# LOOPMUX register map
Vendor: Texas Instruments
Peripheral module from a debugger description file (folder UCD3138R032RSM).
Registers are 32-bit, read-write, no defined reset value unless marked. A register's access mark holds for its fields unless they carry their own. Offsets are as the file gives them; lines under a group give offsets from that group; [hi:lo] are bit positions; {n}, {i} and the like mark numbered series; 'fields as' and 'values as' point back to an identical list; <NAME> marks a mode.

## LOOPMUX — Top Module UCDLOOPMUX
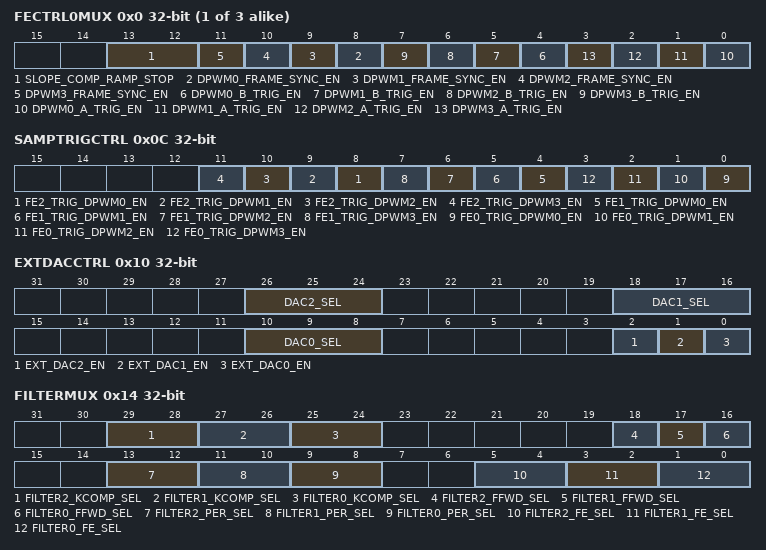
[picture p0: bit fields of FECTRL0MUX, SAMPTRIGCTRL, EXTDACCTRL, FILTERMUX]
{0x0+4i} FECTRL{i}MUX (i=0..2) — Front End Control {i} Mux Register
  [13:12] SLOPE_COMP_RAMP_STOP — Selects the PCMC module source for stop ramp signal in the event of peak current detection
  [n+8] DPWM{n}_FRAME_SYNC_EN (n=0..3) — Enables DPWM Trigger from DPWM {n} Frame Sync to Front End Control
    1=routed (DPWM {n} Frame Sync routed to Front End Control); 0=not_routed (DPWM {n} Frame Sync not routed to Front End Control (Default))
  [n+4] DPWM{n}_B_TRIG_EN (n=0..3) — Enables DPWM Trigger from DPWM {n} PWM-B to Front End Contro
    1=routed (DPWM {n} PWM-B trigger routed to Front End Control); 0=not_routed (DPWM {n} PWM-B trigger not routed to Front End Control (Default))
  [n] DPWM{n}_A_TRIG_EN (n=0..3) — Enables DPWM Trigger from DPWM {n} PWM-A to Front End Contro
    1=routed (DPWM {n} PWM-A trigger routed to Front End Control); 0=not_routed (DPWM {n} PWM-A trigger not routed to Front End Control (Default))
0x0C SAMPTRIGCTRL — Sample Trigger Control Register
  [n+8] FE2_TRIG_DPWM{n}_EN (n=0..3) — Enables Sample Trigger from DPWM {n} to Front End Control 2
    1=routed (DPWM {n} Sample Trigger routed to Front End Control 2); 0=not_routed (DPWM {n} Sample Trigger not routed to Front End Control 2 (Default))
  [n+4] FE1_TRIG_DPWM{n}_EN (n=0..3) — Enables Sample Trigger from DPWM {n} to Front End Control 1
    1=routed (DPWM {n} Sample Trigger routed to Front End Control 1); 0=not_routed (DPWM {n} Sample Trigger not routed to Front End Control 1 (Default))
  [n] FE0_TRIG_DPWM{n}_EN (n=0..3) — Enables Sample Trigger from DPWM {n} to Front End Control 0
    1=routed (DPWM {n} Sample Trigger routed to Front End Control 0); 0=not_routed (DPWM {n} Sample Trigger not routed to Front End Control 0 (Default))
0x10 EXTDACCTRL access per field — External DAC Control Register
  [26:24] DAC2_SEL rw — Configures DAC 2 setpoint in External DAC Mode
    6=FILTER_2 (Filter 2 Output Selected); 5=FILTER_1 (Filter 1 Output Selected); 4=FILTER_0 (Filter 0 Output Selected); 3=CP (Output of Constant Power Module Selected); 1=DAC_1 (DAC 1 Setpoint Selected); 0=DAC_0 (DAC 0 Setpoint Selected (Default))
  [18:16] DAC1_SEL rw — Configures DAC 1 setpoint in External DAC Mode
    6=FILTER_2 (Filter 2 Output Selected); 5=FILTER_1 (Filter 1 Output Selected); 4=FILTER_0 (Filter 0 Output Selected); 3=CP (Output of Constant Power Module Selected); 2=DAC_2 (DAC 2 Setpoint Selected); 0=DAC_0 (DAC 0 Setpoint Selected (Default))
  [10:8] DAC0_SEL rw — Configures DAC 0 setpoint in External DAC Mode
    6=FILTER_2 (Filter 2 Output Selected); 5=FILTER_1 (Filter 1 Output Selected); 4=FILTER_0 (Filter 0 Output Selected); 3=CP (Output of Constant Power Module Selected); 2=DAC_2 (DAC 2 Setpoint Selected); 1=DAC_1 (DAC 1 Setpoint Selected (Default))
  [2] EXT_DAC2_EN rw — External DAC 1 Mode Enable
    1=enable (External DAC Mode enabled, DAC 2 setpoint driven by DAC1_SEL configuration); 0=disabled (External DAC Mode disabled. DAC 2 setpoint driven from Front End Control Module (Default))
  [1] EXT_DAC1_EN rw — External DAC 1 Mode Enable
    1=enable (External DAC Mode enabled, DAC 1 setpoint driven by DAC1_SEL configuration); 0=disabled (External DAC Mode disabled. DAC 1 setpoint driven from Front End Control Module (Default))
  [0] EXT_DAC0_EN rw — External DAC 1 Mode Enable
    1=enable (External DAC Mode enabled, DAC 0 setpoint driven by DAC1_SEL configuration); 0=disabled (External DAC Mode disabled. DAC 0 setpoint driven from Front End Control Module (Default))
0x14 FILTERMUX access per field
  [29:28] FILTER2_KCOMP_SEL rw — Selects KComp value routed to Filter 2 Module
    2=KCOMP_2 (KComp 2 Value Selected); 1=KCOMP_1 (KComp 1 Value Selected); 0=KCOMP_0 (KComp 0 Value Selected (Default))
  [27:26] FILTER1_KCOMP_SEL rw — Selects KComp value routed to Filter 1 Module
    values as FILTER2_KCOMP_SEL
  [25:24] FILTER0_KCOMP_SEL rw — Selects KComp value routed to Filter 0 Module
    values as FILTER2_KCOMP_SEL
  [18] FILTER2_FFWD_SEL rw — Configures Feedforward value routed to Filter 2 Module
    1=FILTER_1 (Filter 1 Value Selected); 0=FILTER_0 (Filter0 Value Selected (Default))
  [17] FILTER1_FFWD_SEL rw — Configures Feedforward value routed to Filter 1 Module
    1=FILTER_2 (Filter 2 Value Selected); 0=FILTER_0 (Filter0 Value Selected (Default))
  [16] FILTER0_FFWD_SEL rw — Configures Feedforward value routed to Filter 0 Module
    1=FILTER_2 (Filter 2 Value Selected); 0=FILTER_1 (Filter 1 Value Selected (Default))
  [13:12] FILTER2_PER_SEL rw — Selects source of switching cycle period for Filter 2 Module
    3=DPWM_3 (DPWM 3 Switching Period); 2=DPWM_2 (DPWM 2 Switching Period); 1=DPWM_1 (DPWM 1 Switching Period); 0=DPWM_0 (DPWM 0 Switching Period (Default))
  [11:10] FILTER1_PER_SEL rw — Selects source of switching cycle period for Filter 1 Module
    values as FILTER2_PER_SEL
  [9:8] FILTER0_PER_SEL rw — Selects source of switching cycle period for Filter 0 Module
    values as FILTER2_PER_SEL
  [5:4] FILTER2_FE_SEL rw — Selects which Front End Module provides data for Filter 2 Module
    2=FE_2 (Front End Module 2 provides data to Filter(Default)); 1=FE_1 (Front End Module 1 provides data to Filter); 0=FE_0 (Front End Module 0 provides data to Filter)
  [3:2] FILTER1_FE_SEL rw — Selects which Front End Module provides data for Filter 1 Module
    2=FE_2 (Front End Module 2 provides data to Filter); 1=FE_1 (Front End Module 1 provides data to Filter(Default)); 0=FE_0 (Front End Module 0 provides data to Filter)
  [1:0] FILTER0_FE_SEL rw — Selects which Front End Module provides data for Filter 0 Module
    2=FE_2 (Front End Module 2 provides data to Filter); 1=FE_1 (Front End Module 1 provides data to Filter); 0=FE_0 (Front End Module 0 provides data to Filter(Default))
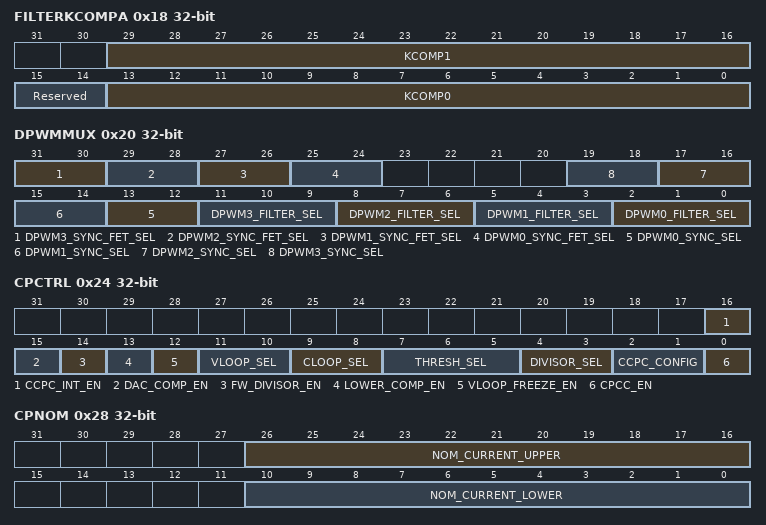
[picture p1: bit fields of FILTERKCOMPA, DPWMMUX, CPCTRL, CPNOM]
0x18 FILTERKCOMPA access per field
  [29:16] KCOMP1 rw — 14-bit value used in filter output calculations replacing the DPWM switching period value
  [15:14] Reserved ro — 14-bit value used in filter output calculations replacing the DPWM switching period value
  [13:0] KCOMP0 rw — 14-bit value used in filter output calculations replacing the DPWM switching period value
0x1C FILTERKCOMPB
  [13:0] KCOMP2 — 14-bit value used in filter output calculations replacing the DPWM switching period value
0x20 DPWMMUX access not given
  [31:30] DPWM3_SYNC_FET_SEL rw — Selects Ramp source for DPWM3 PWM-B SyncFET soft on/off
    2=FE_2 (Front End 2 Ramp output selected); 1=FE_1 (Front End 1 Ramp output selected); 0=FE_0 (Front End 0 Ramp output selected (Default))
  [29:28] DPWM2_SYNC_FET_SEL rw — Selects Ramp source for DPWM2 PWM-B SyncFET soft on/off
    values as DPWM3_SYNC_FET_SEL
  [27:26] DPWM1_SYNC_FET_SEL rw — Selects Ramp source for DPWM1 PWM-B SyncFET soft on/off
    0=FE_2 (Front End 2 Ramp output selected); 0=FE_1 (Front End 1 Ramp output selected); 0=FE_0 (Front End 0 Ramp output selected (Default))
  [25:24] DPWM0_SYNC_FET_SEL rw — Selects Ramp source for DPWM0 PWM-B SyncFET soft on/off
    values as DPWM3_SYNC_FET_SEL
  [2n+13:2n+12] DPWM{n}_SYNC_SEL rw (n=0..3) — Selects Master Sync for DPWM {n} when DPWM {n} configured in slave mode
    3=DPWM_3 (DPWM 3 Sync); 2=DPWM_2 (DPWM 2 Sync); 1=DPWM_1 (DPWM 1 Sync); 0=DPWM_0 (DPWM 0 Sync (Default))
  [3n+2:3n] DPWM{n}_FILTER_SEL (n=0..3) — Selects source of duty cycle/resonant period for DPWM Module {n}
    4=DPWM_ON_TIME; 3=CPCC; 2=Filter_2; 1=Filter_1; 0=Filter_0
0x24 CPCTRL — Constant Power Control Register
  [16] CCPC_INT_EN — Constant Power/Constant Current Interrupt Enable
    1=enable (Interrupt enabled on mode switches); 0=disabled (Interrupt disabled on mode switches (Default))
  [15] DAC_COMP_EN — Enables comparison of DAC Setpoint and quotient of Max Power/Sense Current in Loop Switching Mode. Minimum of DAC setpoint and calculated quotient sets voltage loop setpoint in Constant Voltage and Constant Power modes
    1=Min (Minimum of DAC setpoint and calculated quotient used as Voltage Loop DAC Setpoint); 0=Operating Mode controls Voltage Loop DAC Setpoint (Default)
  [14] FW_DIVISOR_EN — Enables Firmware value for divisor in Constant Power calculations
    1=Firmware (Divisor driven by Firmware Current Register); 0=DIVISOR_SEL (Divisor selected by DIVISOR_SEL (Bits 7:6) (Default))
  [13] LOWER_COMP_EN — Enables output of lowest duty from current or voltage loop when Constant Power Constant Current module controls loop output
    1=lowest_duty (Loop output controlled by lowest duty from voltage or current loops); 0=DIVISOR_SEL (Loop output controlled by mode selection, voltage loop selected in constant voltage and constant power mode, current loop selected in constant current mode (Default))
  [12] VLOOP_FREEZE_EN — Enables freezing of Voltage Loop Integrator when current loop selected in Loop Switching configuration
    1=enabled (Freezing of Voltage Loop Integrator enabled); 0=Disabled (Freezing of Voltage Loop Integrator disabled (Default))
  [11:10] VLOOP_SEL — Configures voltage loop for loop switching mode
    2=Filter 2 Output Selected; 1=Filter 1 Output Selected; 0=Filter 0 Output Selected (Default)
  [9:8] CLOOP_SEL — Configures current loop for loop switching mode
    values as VLOOP_SEL
  [7:5] THRESH_SEL — Configures input threshold selected for use in Constant Power comparison
    5=FE_2 (Front End 2 Absolute Value Data Selected); 4=FE_1 (Front End 1 Absolute Value Data Selected); 3=FE_0 (Front End 0 Absolute Value Data Selected); 2=Filter 2 Output Selected; 1=Filter 1 Output Selected; 0=Filter 0 Output Selected (Default)
  [4:3] DIVISOR_SEL — Configures value used for divisor in Constant Power calculations
    2=FE_2 (Front End 2 Absolute Value Data Selected); 1=FE_1 (Front End 1 Absolute Value Data Selected); 0=FE_0 (Front End 0 Absolute Value Data Selected(default))
  [2:1] CCPC_CONFIG — Controls Constant Power/Constant Current module configuration
    1=Constant Power Module controls selection of voltage/current loop; 0=Average Current Mode (Default)
  [0] CPCC_EN — Constant Power Constant/Current Module Enable
    1=enable (Constant Power/Constant Current Module enabled); 0=disabled (Constant Power/Constant Current Module disabled (Default))
0x28 CPNOM access per field — Constant Power Nominal Threshold Register
  [26:16] NOM_CURRENT_UPPER rw — Configures INOM value used in Constant Power/Constant Current Calculations, when sensed value exceeds NOM_CURRENT_UPPER in Constant Voltage mode, setpoint will switch to Constant Power mode
  [10:0] NOM_CURRENT_LOWER rw — Configures INOM value used in Constant Power/Constant Current Calculations, when sensed value falls below NOM_CURRENT_LOWER in Constant Power mode, setpoint will switch to Constant Voltage mode
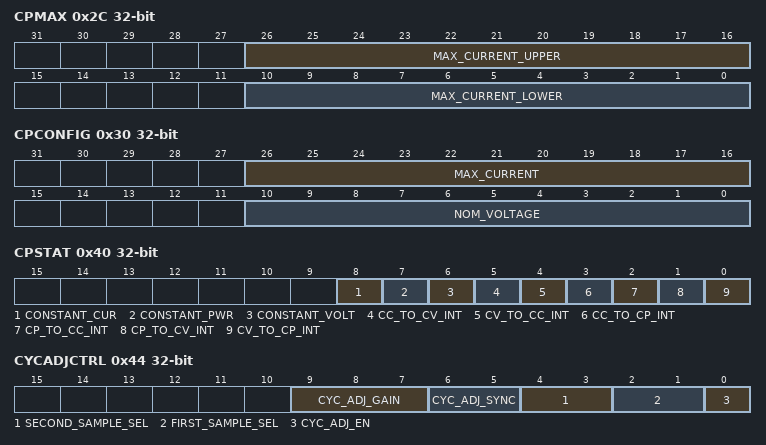
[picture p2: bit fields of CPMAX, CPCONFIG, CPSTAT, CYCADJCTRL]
0x2C CPMAX access per field — Constant Power Max Threshold Register
  [26:16] MAX_CURRENT_UPPER rw — Configures IMAX value used in Constant Power/Constant Current Calculations, when sensed value exceeds MAX_CURRENT_UPPER in Constant Power mode, setpoint will switch to Max Current mode
  [10:0] MAX_CURRENT_LOWER rw — Configures IMAX value used in Constant Power/Constant Current Calculations, when sensed value falls below MAX_CURRENT_LOWER in Max Current mode, setpoint will switch to Constant Power mode
0x30 CPCONFIG access per field — Constant Power Configuration Register
  [26:16] MAX_CURRENT rw — Configures IMAX setpoint used in Constant Power/Constant Current Calculations in Max Current mode
  [10:0] NOM_VOLTAGE rw — Configures VNOM setpoint used in Constant Power/Constant Current Calculations in Constant Voltage mode (Loop Oring configuration selected)
0x34 CPMAXPWR — Constant Power Max Power Register
  [21:0] MAX_POWER — Configures PMAX value used in Constant Power/Constant Current calculations in Constant Power mode
0x38 CPINTTHRESH — Constant Power Integrator Threshold Register
  [23:0] INT_THRESH — 24-bit signed value added to Current Loop Duty value to determine when to freeze Current Loop Integrator
0x3C CPFWDIVISOR — Constant Power Firmware Divisor Register
  [10:0] FW_DIVISOR — 10-bit value used in Constant Power calculation when firmware value is selected in Bit 17 of Constant Power Control Register
0x40 CPSTAT ro — Constant Power Status Register
  [8] CONSTANT_CUR — Constant Current Mode Indication
    1=enaabled (Constant Current Mode enabled); 0=not_enabled (Constant Current Mode not enabled)
  [7] CONSTANT_PWR — Constant Power Mode Indication
    1=enabled (Constant Power Mode enabled); 0=not_enabled (Constant Power Mode not enabled)
  [6] CONSTANT_VOLT — Constant Voltage Mode Indication
    1=ensabled (Constant Voltage Mode enabled); 0=not_enabled (Constant Voltage Mode not enabled)
  [5] CC_TO_CV_INT — Constant Current Mode to Constant Voltage Mode latched status, cleared on read
    1=Transition from Constant Current to Constant Voltage detected; 0=no_tarnsition (No transition from Constant Current to Constant Voltage detected)
  [4] CV_TO_CC_INT — Constant Voltage Mode to Constant Current Mode latched status, cleared on read
    1=Transition from Constant Voltage to Constant Current detected; 0=no_tarnsition (No transition from Constant Voltage to Constant Current detected)
  [3] CC_TO_CP_INT — Constant Current Mode to Constant Power Mode latched status, cleared on read
    1=Transition from Constant Current to Constant Power detected; 0=no_tarnsition (No transition from Constant Current to Constant Power detected)
  [2] CP_TO_CC_INT — Constant Power Mode to Constant Current Mode latched status, cleared on read
    1=Transition from Constant Power to Constant Current detected; 0=no_tarnsition (No transition from Constant Power to Constant Current detected)
  [1] CP_TO_CV_INT — Constant Power Mode to Constant Voltage Mode latched status, cleared on read
    1=Transition from Constant Power to Constant Voltage detected; 0=no_tarnsition (No transition from Constant Power to Constant Voltage detected)
  [0] CV_TO_CP_INT — Constant Voltage Mode to Constant Power Mode latched status, cleared on read
    1=Transition from Constant Voltage to Constant Power detected; 0=no_tarnsition (No transition from Constant Voltage to Constant Power detected)
0x44 CYCADJCTRL — Cycle Adjustment Control Register
  [9:7] CYC_ADJ_GAIN — Configures gain of Cycle Adjustment calculation
    7=x_128 (128x gain); 6=x_64 (64x gain); 5=x_32 (32x gain); 4=x_16 (16x gain); 3=x_8 (8x gain); 2=x_4 (4x gain); 1=x_2 (2x gain); 0=1x gain (Default)
  [6:5] CYC_ADJ_SYNC — Selects which DPWM A trigger synchronizes cycle adjustment calculation, first 2 samples after receipt of DPWM A trigger will be used for Cycle Adjustment Calculation
    3=DPWM_4_A (DPWM-4A trigger selected); 2=DPWM_3_A (DPWM-3A trigger selected); 1=DPWM_2_A (DPWM-2A trigger selected); 0=DPWM_1_A (DPWM-1A trigger selected (Default))
  [4:3] SECOND_SAMPLE_SEL — Configures Front End Module Data used for Second Sample of Cycle Adjustment Calculation
    2=FE_2 (Front End Module 2 Error Data selected); 1=FE_1 (Front End Module 1 Error Data selected); 0=FE_0 (Front End Module 0 Error Data selected (Default))
  [2:1] FIRST_SAMPLE_SEL — Configures Front End Module Data used for First Sample of Cycle Adjustment Calculation
    values as SECOND_SAMPLE_SEL
  [0] CYC_ADJ_EN — Cycle Adjustment Calculation Enable
    1=enabled (Cycle Adjustment Calculation enabled); 0=disabled (Cycle Adjustment Calculation disabled (Default))
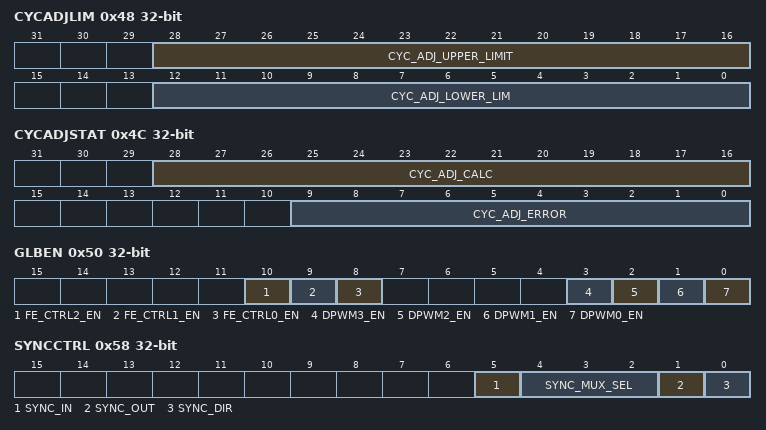
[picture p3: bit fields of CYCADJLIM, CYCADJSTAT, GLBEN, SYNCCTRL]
0x48 CYCADJLIM access per field — Constant Power Configuration Register
  [28:16] CYC_ADJ_UPPER_LIMIT rw — Cycle Adjustment Calculation signed upper limit value, output of Cycle Adjustment Calculation is clamped at the upper limit, if calculated result exceeds the upper limit. LSB resolution equals High Frequency Oscillator period/16
  [12:0] CYC_ADJ_LOWER_LIM rw — Cycle Adjustment Calculation signed lower limit value, output of Cycle Adjustment Calculation is clamped at the lower limit, if calculated result falls below the lower limit. LSB resolution equals High Frequency Oscillator period/16
0x4C CYCADJSTAT ro — Cycle Adjustment Status Register
  [28:16] CYC_ADJ_CALC — 13-bit signed value representing calculated Cycle Adjustment provided to DPWM module based on first 2 error samples
  [9:0] CYC_ADJ_ERROR — 10-bit signed value representing calculated error of the first 2 error samples received
0x50 GLBEN access per field — Global Enable Register
  [10] FE_CTRL2_EN rw — Global Firmware Enable for Front End Control 2 Module
    1=enabled (Front End Control 2 Module Enabled); 0=not_enabled (Front End Control 2 Module Disabled (Default))
  [9] FE_CTRL1_EN rw — Global Firmware Enable for Front End Control 1 Module
    1=enabled (Front End Control 1 Module Enabled); 0=not_enabled (Front End Control 1 Module Disabled (Default))
  [8] FE_CTRL0_EN rw — Global Firmware Enable for Front End Control 0 Module
    1=enabled (Front End Control 0 Module Enabled); 0=not_enabled (Front End Control 0 Module Disabled (Default))
  [3] DPWM3_EN rw — Global Firmware Enable for DPWM 3 Module
    1=enabled (DPWM 3 Module Enabled); 0=not_enabled (DPWM 3 Module Disabled (Default))
  [2] DPWM2_EN rw — Global Firmware Enable for DPWM 2 Module
    values as DPWM3_EN
  [1] DPWM1_EN rw — Global Firmware Enable for DPWM 1 Module
    1=enabled (DPWM 1 Module Enabled); 0=not_enabled (DPWM 1 Module Disabled (Default))
  [0] DPWM0_EN rw — Global Firmware Enable for DPWM 0 Module
    1=enabled (DPWM 0 Module Enabled); 0=not_enabled (DPWM 0 Module Disabled (Default))
0x54 PWMGLBPRD access per field — PWM Global Period Register
  [17:4] PRD rw — Global PWM Period value, overriding DPWM Period settings when global PWM period is selected within each DPWM module
0x58 SYNCCTRL access per field — Sync Control Register
  [5] SYNC_IN ro — Value of Sync pin
    1=high (Logic level high present on Sync pin); 0=low (Logic level low present on Sync pin)
  [4:2] SYNC_MUX_SEL rw — Selects which module controls Sync pin output
    7=LOW_DRIVEN (Driven low); 6=LFO_CLK (Low-Frequency Oscillator Clock Output); 5=CLKSR_CLKCNTL (Value specified by CLKSR in CLKCNTL); 4=SYNC_OUT (Value from SYNC_OUT (Bit 1)); 3=DPWM_3 (DPWM 3 Sync Output); 2=DPWM_2 (DPWM 2 Sync Output (Default)); 1=DPWM_1 (DPWM 1 Sync Output); 0=DPWM_0 (DPWM 0 Sync Output (Default))
  [1] SYNC_OUT rw — Configure output value for Sync pin, if used as an output
    1=high (Sync pin driven high in output mode (Default)); 0=low (Sync pin driven low in output mode)
  [0] SYNC_DIR rw — Configure direction of Sync pin
    1=input (Sync pin configured as an input pin (Default)); 0=output (Sync pin configured as an output pin)
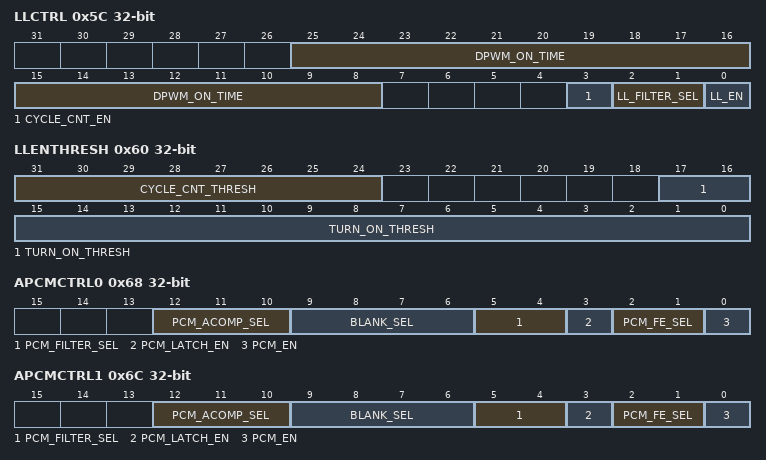
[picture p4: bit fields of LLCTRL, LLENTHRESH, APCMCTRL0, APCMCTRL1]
0x5C LLCTRL access per field — Light Load Control Register
  [25:8] DPWM_ON_TIME rw — DPWM pulse width used for EADC-based light load mode operation, when selected Filter data exceeds TURN_ON_THRESH value
  [3] CYCLE_CNT_EN rw — Enables Switching Cycle Counter for enabling constant pulse widths when configured in Light Load operation
    1=enabled (Switching Cycle Counter enabled); 0=disabled (Switching Cycle Counter disabled (Default))
  [2:1] LL_FILTER_SEL rw — Configures source of filter data for Light Load comparisons
    1=FILTER_2 (Filter 2 data selected); 1=FILTER_1 (Filter 1 data selected); 0=FILTER_0 (Filter 0 data selected (Default))
  [0] LL_EN rw — EADC-based Light Load Mode Enable
    1=enabled (Light Load Mode enabled); 0=disabled (Light Load Mode disabled (Default))
0x60 LLENTHRESH access per field — Light Load Enable Threshold Register
  [31:24] CYCLE_CNT_THRESH rw — Switching Cycle threshold where constant width DPWM pulses are enabled when number of switching cycles without pulses exceeds threshold
  [17:0] TURN_ON_THRESH rw — Filter data threshold where constant width DPWM pulses are enabled when filter data exceeds threshold
0x64 LLDISTHRESH — Light Load Disable Threshold Register
  [17:0] TURN_OFF_THRESH — Filter data threshold where constant width DPWM pulses are disabled when filter data falls below threshold
0x68 APCMCTRL0 access not given — Analog Peak Current Mode Control 0 Register
  [12:10] PCM_ACOMP_SEL — Selects source of analog comparator output for APCMC
    5=ACOMPF; 4=ACOMPE; 3=ACOMPD; 2=ACOMPC; 1=ACOMPB; 0=ACOMPA
  [9:6] BLANK_SEL rw — DPWM source for blank signal
    3=DPWM3 (Blank signal from DPWM0); 2=DPWM2 (Blank signal from DPWM2); 1=DPWM1 (Blank signal from DPWM1); 0=DPWM0 (Blank signal from DPWM0)
  [5:4] PCM_FILTER_SEL rw — Selects source of Peak Current Slope Compensation Ramp Start
    3=CPCC (CPCC data selected); 2=Filter 2 data selected; 1=Filter 1 data selected; 0=Filter 0 data selected
  [3] PCM_LATCH_EN rw — Enables latching of Peak Current Flag to end of frame
    1=latched (PCM Flag is latched to end of PCM Frame); 0=not_latched (PCM Flag is not latched to end of PCM Frame (Default))
  [2:1] PCM_FE_SEL rw — Selects source of AFE comparator output for APCMC
    3=ACOMP (analog comparator); 2=AFE2 (Front end 2); 1=AFE1 (Front end 1); 0=AFE0 (Front end 0)
  [0] PCM_EN rw — Analog Peak Current Mode Control Module Enable
    1=enabled (Analog Peak Current Mode Control Module enabled); 0=disabled (Analog Peak Current Mode Control Module disabled (Default))
0x6C APCMCTRL1 — Analog peak current mode control 1 register
  [12:10] PCM_ACOMP_SEL — Selects source of analog comparator output for analog peak current mode control
  [9:6] BLANK_SEL — DPWM source for blank signal
  [5:4] PCM_FILTER_SEL — Selects source of peak current compensation ramp start
  [3] PCM_LATCH_EN — Enables latching of peak current control flag to end frame
  [2:1] PCM_FE_SEL — Selects source of FE comparator output for analog peak current control
  [0] PCM_EN — Analog peak current mode control module enable
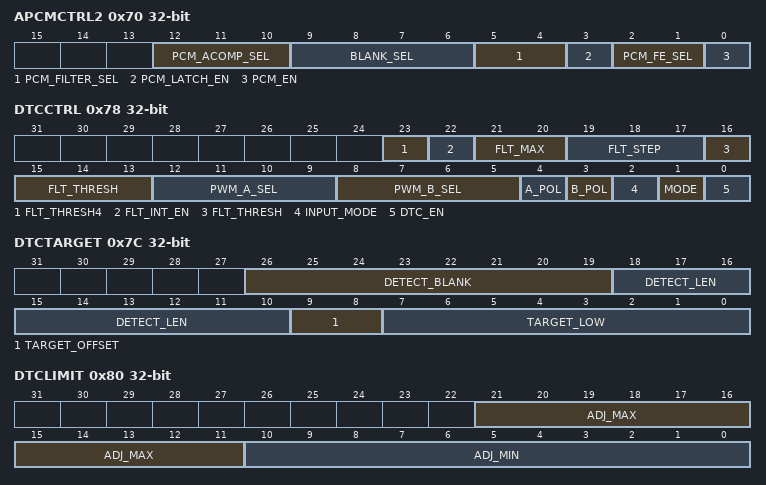
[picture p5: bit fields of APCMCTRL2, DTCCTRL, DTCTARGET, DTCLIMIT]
0x70 APCMCTRL2 — Analog peak current control 2 register
  [12:10] PCM_ACOMP_SEL — Selects source of analog comparator output for Analog Peak Current Mode Control
  [9:6] BLANK_SEL — DPWM source for blank signal
  [5:4] PCM_FILTER_SEL — Selects source of Peak Current Slope Compensation Ramp Start
  [3] PCM_LATCH_EN — Enables latching of Peak Current Flag to end of frame
  [2:1] PCM_FE_SEL — Selects source of Front-End Comparator output for Analog Peak Current Mode Control
  [0] PCM_EN — Analog Peak Current Mode Control Module Enable
0x78 DTCCTRL access not given — DTC control register
  [23] FLT_THRESH4 rw — MSB of fault threshold
  [22] FLT_INT_EN rw — Enables interrupt generation when a fault flag condition has been met
  [21:20] FLT_MAX rw — Sets the number of consecutive detected faults before a fault step is utilized
  [19:17] FLT_STEP rw — Sets the negative step size when a fault condition is detected that exceeds the fault max value
  [16:13] FLT_THRESH rw — Fault threshold
  [12:9] PWM_A_SEL rw — Selects the phase A negative edge reference to begin a measurement window
  [8:5] PWM_B_SEL rw — Selects the phase B negative edge reference to begin a measurement window
  [4] A_POL rw — Signal polarity of the DTC input
  [3] B_POL rw — Signal polarity of the DTC input
  [2] INPUT_MODE rw — Sets the input method for the DTC module
  [1] MODE — Sets mode control of the DTC phase accumulator value
  [0] DTC_EN rw — DTC enable
0x7C DTCTARGET access not given
  [26:19] DETECT_BLANK rw — Sets the target measurement window blanking length, in HFO clock increments
  [18:10] DETECT_LEN rw — Sets the target measurement window length, in HFO clock increments
  [9:8] TARGET_OFFSET rw — Target threshold offset
  [7:0] TARGET_LOW — Target lower threshold
0x80 DTCLIMIT — DTC Auto Control Limit Register
  [21:11] ADJ_MAX — Sets the signed integer upper clamp for the accumulators.
  [10:0] ADJ_MIN — Sets the signed integer lower clamp for the accumulators.
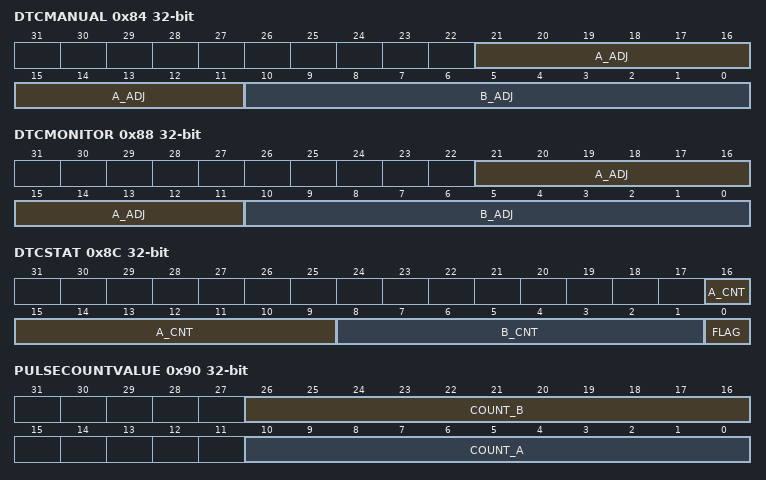
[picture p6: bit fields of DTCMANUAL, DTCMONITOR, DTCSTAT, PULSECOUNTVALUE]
0x84 DTCMANUAL — DTC Manual Control Register
  [21:11] A_ADJ — Sets the signed A accumulator value when manual control is enabled.
  [10:0] B_ADJ — Sets the signed A accumulator value when manual control is enabled.
0x88 DTCMONITOR ro
  [21:11] A_ADJ — Monitored accumulator A value from the DTC module
  [10:0] B_ADJ — Monitored accumulator B value from the DTC module
0x8C DTCSTAT ro — DTC Status Register
  [16:9] A_CNT — Last measurement value for phase A input signal
  [8:1] B_CNT — Last measurement value for phase B input signal
  [0] FLAG — Flag is set when the fault count exceeds the FLT MAX value programmed in the DTCCTRL register.
0x90 PULSECOUNTVALUE ro
  [26:16] COUNT_B — Pulse count value B on DTC1 pin
  [10:0] COUNT_A — Pulse count value A on DTC1 pin
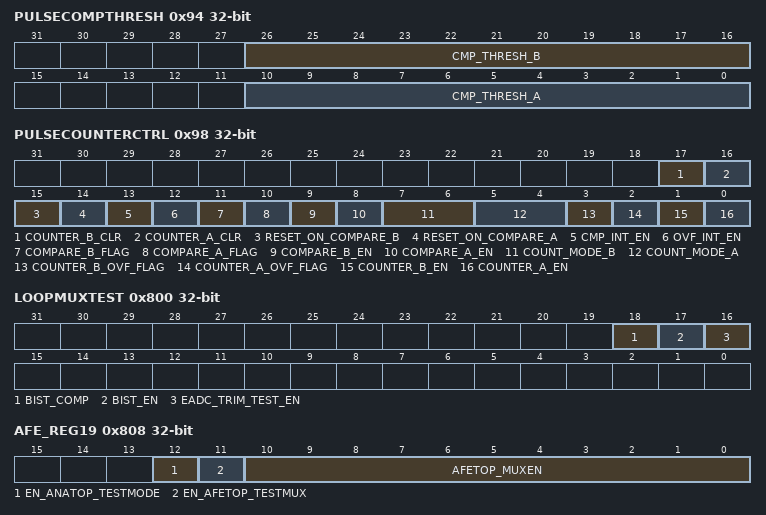
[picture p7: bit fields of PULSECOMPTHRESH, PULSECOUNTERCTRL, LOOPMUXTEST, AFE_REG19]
0x94 PULSECOMPTHRESH access per field — Pulse compare threshold register
  [26:16] CMP_THRESH_B rw — Pulse counter B compare threshold
  [10:0] CMP_THRESH_A rw — Pulse counter B compare threshold
0x98 PULSECOUNTERCTRL access per field — Pulse counter control register
  [17] COUNTER_B_CLR rw — Counter B clear
  [16] COUNTER_A_CLR rw — Counter A clear
  [15] RESET_ON_COMPARE_B rw — Enable reset of counter B on compare B event
  [14] RESET_ON_COMPARE_A rw — Enable reset of counter A on compare A event
  [13] CMP_INT_EN rw — Enable interrupt on compare A or B match
  [12] OVF_INT_EN rw
  [11] COMPARE_B_FLAG ro — Compare B match flag. Clears on read
  [10] COMPARE_A_FLAG ro — Compare A match flag. Clears on read
  [9] COMPARE_B_EN rw — Enables compare B
  [8] COMPARE_A_EN rw — Enables compare A
  [7:6] COUNT_MODE_B rw — Selects the countting mode for counter B
  [5:4] COUNT_MODE_A rw — Seelects the counting mode for counter A
  [3] COUNTER_B_OVF_FLAG ro — Counter B overflow flag
  [2] COUNTER_A_OVF_FLAG ro — Counter A overflow flag
  [1] COUNTER_B_EN rw — Enables counter B
  [0] COUNTER_A_EN rw — Enables counter A
0x800 LOOPMUXTEST access per field — Loop Mux Test Register (Test Use Only)
  [18] BIST_COMP ro — High-Speed Loop BIST Complete Status
    1=complete (High-Speed Loop BIST completed); 0=not_complete (High-Speed Loop BIST not complete)
  [17] BIST_EN rw — High-Speed Loop BIST Enable
    1=enabled (High-Speed Loop BIST enabled); 0=disabled (High-Speed Loop BIST disabled (Default))
  [16] EADC_TRIM_TEST_EN rw — EADC Trim Test Mode Enable
    1=enabled (EADC Trim Test Mode enabled, bits 15:0 provided to all 3 Analog Front End modules); 0=disabled (EADC Trim Test Mode disabled (Default))
0x804 EADC_TRIM_TEST
  [31:0] EADC_TEST_TRIM — EADC test trim bits
0x808 AFE_REG19 — AFE register 19 for analog (For Factory Test Use Only)
  [12] EN_ANATOP_TESTMODE — AFE TOP test mode enable
  [11] EN_AFETOP_TESTMUX — AFE TOP test mux enable
  [10:0] AFETOP_MUXEN — AFE TOP Mux enable
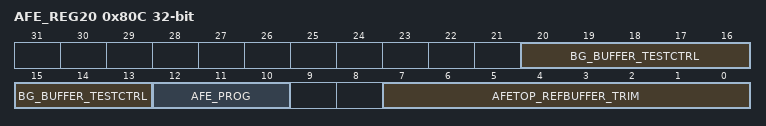
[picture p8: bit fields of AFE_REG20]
0x80C AFE_REG20 access per field — AFE register 20 for analog (For Factory Test Use Only)
  [20:13] BG_BUFFER_TESTCTRL rw — BG buffer test control bits
  [12:10] AFE_PROG rw — Indicates trimming mode
  [7:0] AFETOP_REFBUFFER_TRIM rw — Trim bits for more accurate Vref buffer for EADC and EDAC
0x810 AFE_LOOPMUX_SPARE
